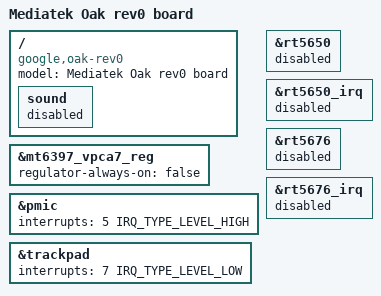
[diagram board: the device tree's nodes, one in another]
/*
 * Copyright (c) 2014 MediaTek Inc.
 * Author: Eddie Huang <eddie.huang@mediatek.com>
 *
 * This program is free software; you can redistribute it and/or modify
 * it under the terms of the GNU General Public License version 2 as
 * published by the Free Software Foundation.
 *
 * This program is distributed in the hope that it will be useful,
 * but WITHOUT ANY WARRANTY; without even the implied warranty of
 * MERCHANTABILITY or FITNESS FOR A PARTICULAR PURPOSE.  See the
 * GNU General Public License for more details.
 */

/dts-v1/;
#include "mt8173-oak.dtsi"

/ {
	model = "Mediatek Oak rev0 board";
	compatible = "google,oak-rev0", "google,oak", "mediatek,mt8173";

	sound {
		status = "disabled";
	};
};

&mt6397_vpca7_reg {
	regulator-always-on = "false";
};

&pmic {
	interrupts = <5 IRQ_TYPE_LEVEL_HIGH>;
};

&rt5650 {
	status = "disabled";
};

&rt5650_irq {
	status = "disabled";
};

&rt5676 {
	status = "disabled";
};

&rt5676_irq {
	status = "disabled";
};

&trackpad {
	interrupts = <7 IRQ_TYPE_LEVEL_LOW>;
};
